AUTOSAR XML (schema 321)
package /ComponentType
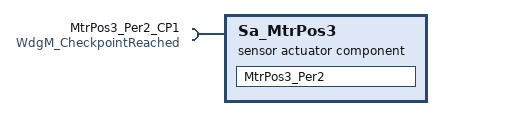
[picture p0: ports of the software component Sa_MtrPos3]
  sensor actuator software component type Sa_MtrPos3
    require port MtrPos3_Per2_CP1: client-com-spec=CheckpointReached, required-interface=WdgM_CheckpointReached
  internal behavior Sa_MtrPos3_InternalBehavior: component=Sa_MtrPos3, port-api-option{enable-take-address=false, indirect-api=false, port=MtrPos3_Per2_CP1}
    runnable MtrPos3_Per2
      sync call SC_MtrPos3_Per2_CP1_CheckpointReached: operation=MtrPos3_Per2_CP1.CheckpointReached, timeout=0
  swc implementation Sa_MtrPos3_Implementation: behavior=Sa_MtrPos3_InternalBehavior
    code-descriptors:
      code Code: type=SRC
package /PortInterface
  client server interface WdgM_CheckpointReached: is-service=true
    operation CheckpointReached: possible-error=E_NOT_OK  # Indicates to the Watchdog Manager that a Checkpoint within a Supervised Entity has been reached.
    error E_NOT_OK: error-code=1
